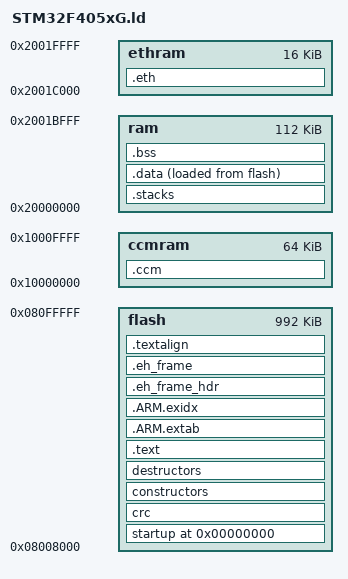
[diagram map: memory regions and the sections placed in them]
/*
 * ST32F405xG memory setup.
 */
__main_stack_size__     = 0x0400;
__process_stack_size__  = 0x0400;

MEMORY
{
    flash : org = 0x08008000, len = 1M-32k
    ram : org = 0x20000000, len = 112k
    ethram : org = 0x2001C000, len = 16k
    ccmram : org = 0x10000000, len = 64k
}

__ram_start__           = ORIGIN(ram);
__ram_size__            = LENGTH(ram);
__ram_end__             = __ram_start__ + __ram_size__;

__crc_start__		= ORIGIN(flash) + 0x1AC;

ENTRY(ResetHandler)

SECTIONS
{
    . = 0;
    _text = .;

    startup : ALIGN(16) SUBALIGN(16)
    {
        KEEP(*(vectors))
    } > flash

    crc __crc_start__ :
    {
        LONG(0x55AA11EE);
    } > flash

    constructors : ALIGN(4) SUBALIGN(4)
    {
        PROVIDE(__init_array_start = .);
        KEEP(*(SORT(.init_array.*)))
        KEEP(*(.init_array))
        PROVIDE(__init_array_end = .);
    } > flash

    destructors : ALIGN(4) SUBALIGN(4)
    {
        PROVIDE(__fini_array_start = .);
        KEEP(*(.fini_array))
        KEEP(*(SORT(.fini_array.*)))
        PROVIDE(__fini_array_end = .);
    } > flash

    .text : ALIGN(16) SUBALIGN(16)
    {
        *(.text.startup.*)
        *(.text)
        *(.text.*)
        *(.rodata)
        *(.rodata.*)
        *(.glue_7t)
        *(.glue_7)
        *(.gcc*)
    } > flash

    .ARM.extab :
    {
        *(.ARM.extab* .gnu.linkonce.armextab.*)
    } > flash

    .ARM.exidx : {
        PROVIDE(__exidx_start = .);
        *(.ARM.exidx* .gnu.linkonce.armexidx.*)
        PROVIDE(__exidx_end = .);
     } > flash

    .eh_frame_hdr :
    {
        *(.eh_frame_hdr)
    } > flash

    .eh_frame : ONLY_IF_RO
    {
        *(.eh_frame)
    } > flash
    
    .textalign : ONLY_IF_RO
    {
        . = ALIGN(8);
    } > flash

    . = ALIGN(4);
    _etext = .;
    _textdata = _etext;

    .ccm (NOLOAD):
    {
        PROVIDE(_ccm_start = .);
        . = ALIGN(4);
        *(.ccm)
        . = ALIGN(4);
        *(.ccm.*)
        . = ALIGN(4);
        PROVIDE(_ccm_end = .);
    } > ccmram

    .stacks :
    {
        . = ALIGN(8);
        __main_stack_base__ = .;
        . += __main_stack_size__;
        . = ALIGN(8);
        __main_stack_end__ = .;
        __process_stack_base__ = .;
        __main_thread_stack_base__ = .;
        . += __process_stack_size__;
        . = ALIGN(8);
        __process_stack_end__ = .;
        __main_thread_stack_end__ = .;
    } > ram

    .data ALIGN(4) : ALIGN(4)
    {
        . = ALIGN(4);
        PROVIDE(_data = .);
        *(.data)
        *(.data.*)
        *(.ramtext)
        . = ALIGN(4);
        PROVIDE(_edata = .);
    } > ram AT > flash

    .bss ALIGN(4) : ALIGN(4)
    {
        . = ALIGN(4);
        PROVIDE(_bss_start = .);
        *(.bss)
        *(.bss.*)
        *(COMMON)
        . = ALIGN(4);
        PROVIDE(_bss_end = .);
    } > ram

    .eth (NOLOAD):
    {
        PROVIDE(_dma_start = .);
        . = ALIGN(4);
        *(.eth)
        . = ALIGN(4);
        *(.eth.*)
        . = ALIGN(4);
        PROVIDE(_dma_end = .);
    } > ethram
}

PROVIDE(end = .);
_end            = .;

__heap_base__   = _end;
__heap_end__    = __ram_end__;
